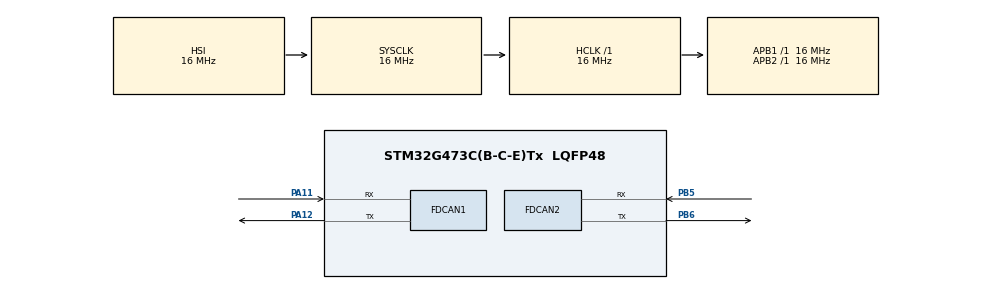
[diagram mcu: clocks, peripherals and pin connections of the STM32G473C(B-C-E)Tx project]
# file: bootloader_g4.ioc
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FDCAN1.AutoRetransmission=ENABLE
FDCAN1.CalculateBaudRateNominal=62500
FDCAN1.CalculateTimeBitNominal=16000
FDCAN1.CalculateTimeQuantumNominal=1000.0
FDCAN1.DataTimeSeg1=1
FDCAN1.DataTimeSeg2=1
FDCAN1.NominalSyncJumpWidth=8
FDCAN1.NominalTimeSeg1=13
FDCAN1.StdFiltersNbr=28
FDCAN2.AutoRetransmission=ENABLE
FDCAN2.CalculateBaudRateNominal=125000
FDCAN2.CalculateTimeBitNominal=8000
FDCAN2.CalculateTimeQuantumNominal=500.0
FDCAN2.NominalPrescaler=8
FDCAN2.NominalTimeSeg1=13
FDCAN2.StdFiltersNbr=28
Mcu.Family=STM32G4
Mcu.Name=STM32G473C(B-C-E)Tx
Mcu.Package=LQFP48
NVIC.FDCAN1_IT0_IRQn=true\:0\:0\:false\:false\:true\:true\:true\:true
NVIC.FDCAN1_IT1_IRQn=true\:0\:0\:false\:false\:true\:true\:true\:true
NVIC.PriorityGroup=NVIC_PRIORITYGROUP_4
PA11.Mode=FDCAN_Activate
PA11.Signal=FDCAN1_RX
PA12.Mode=FDCAN_Activate
PA12.Signal=FDCAN1_TX
PB5.Mode=FDCAN_Activate
PB5.Signal=FDCAN2_RX
PB6.Mode=FDCAN_Activate
PB6.Signal=FDCAN2_TX
ProjectManager.HeapSize=0x200
ProjectManager.StackSize=0x400
ProjectManager.TargetToolchain=STM32CubeIDE
RCC.AHBFreq_Value=16000000
RCC.APB1Freq_Value=16000000
RCC.APB1TimFreq_Value=16000000
RCC.APB2Freq_Value=16000000
RCC.APB2TimFreq_Value=16000000
RCC.CortexFreq_Value=16000000
RCC.EXTERNAL_CLOCK_VALUE=12288000
RCC.HCLKFreq_Value=16000000
RCC.HSE_VALUE=8000000
RCC.HSI48_VALUE=48000000
RCC.HSI_VALUE=16000000
RCC.LSE_VALUE=32768
RCC.SYSCLKFreq_VALUE=16000000
RCC.USBFreq_Value=64000000
RCC.VCOOutputFreq_Value=128000000
VP_SYS_VS_DBSignals.Mode=DisableDeadBatterySignals
board=custom

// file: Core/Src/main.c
/* USER CODE BEGIN Header */
/**
 ******************************************************************************
 * @file           : main.c
 * @brief          : Main program body
 ******************************************************************************
 * @attention
 *
 * Copyright (c) 2024 STMicroelectronics.
 * All rights reserved.
 *
 * This software is licensed under terms that can be found in the LICENSE file
 * in the root directory of this software component.
 * If no LICENSE file comes with this software, it is provided AS-IS.
 *
 ******************************************************************************
 */
/* USER CODE END Header */
#include "main.h"
#include "fdcan.h"

#include "canopen_bootloader.h"

/* USER CODE BEGIN PD */

#define BOOTLOADER_WAIT_SECONDS 10 // 5 seconds is probably reasonable time

/* USER CODE END PD */

/* USER CODE BEGIN PV */
int seconds = 0;
bool app_is_in_flash;

/* USER CODE END PV */

void SystemClock_Config(void);

int main(void) {

  /* MCU Configuration--------------------------------------------------------*/

  /* Reset of all peripherals, Initializes the Flash interface and the Systick.
   */
  HAL_Init();

  /* Configure the system clock */
  SystemClock_Config();

  /* Initialize all configured peripherals */
  MX_FDCAN1_Init();
  MX_FDCAN2_Init();
  /* USER CODE BEGIN 2 */

  canopen_bootloader_run();

  /* USER CODE END 2 */

  /* Infinite loop */
  while (1) {
  }
}

void SystemClock_Config(void) {
  RCC_OscInitTypeDef RCC_OscInitStruct = {0};
  RCC_ClkInitTypeDef RCC_ClkInitStruct = {0};

  /** Configure the main internal regulator output voltage
   */
  HAL_PWREx_ControlVoltageScaling(PWR_REGULATOR_VOLTAGE_SCALE1);

  /** Initializes the RCC Oscillators according to the specified parameters
   * in the RCC_OscInitTypeDef structure.
   */
  RCC_OscInitStruct.OscillatorType = RCC_OSCILLATORTYPE_HSI;
  RCC_OscInitStruct.HSIState = RCC_HSI_ON;
  RCC_OscInitStruct.HSICalibrationValue = RCC_HSICALIBRATION_DEFAULT;
  RCC_OscInitStruct.PLL.PLLState = RCC_PLL_NONE;
  if (HAL_RCC_OscConfig(&RCC_OscInitStruct) != HAL_OK) {
    Error_Handler();
  }

  /** Initializes the CPU, AHB and APB buses clocks
   */
  RCC_ClkInitStruct.ClockType = RCC_CLOCKTYPE_HCLK | RCC_CLOCKTYPE_SYSCLK |
                                RCC_CLOCKTYPE_PCLK1 | RCC_CLOCKTYPE_PCLK2;
  RCC_ClkInitStruct.SYSCLKSource = RCC_SYSCLKSOURCE_HSI;
  RCC_ClkInitStruct.AHBCLKDivider = RCC_SYSCLK_DIV1;
  RCC_ClkInitStruct.APB1CLKDivider = RCC_HCLK_DIV1;
  RCC_ClkInitStruct.APB2CLKDivider = RCC_HCLK_DIV1;

  if (HAL_RCC_ClockConfig(&RCC_ClkInitStruct, FLASH_LATENCY_0) != HAL_OK) {
    Error_Handler();
  }
}

void Error_Handler(void) {
  __disable_irq();
  while (1) {
  }
}

#ifdef USE_FULL_ASSERT
/**
 * @brief  Reports the name of the source file and the source line number
 *         where the assert_param error has occurred.
 * @param  file: pointer to the source file name
 * @param  line: assert_param error line source number
 * @retval None
 */
void assert_failed(uint8_t *file, uint32_t line) {
  /* USER CODE BEGIN 6 */
  /* User can add his own implementation to report the file name and line
     number, ex: printf("Wrong parameters value: file %s on line %d\r\n", file,
     line) */
  /* USER CODE END 6 */
}
#endif /* USE_FULL_ASSERT */
